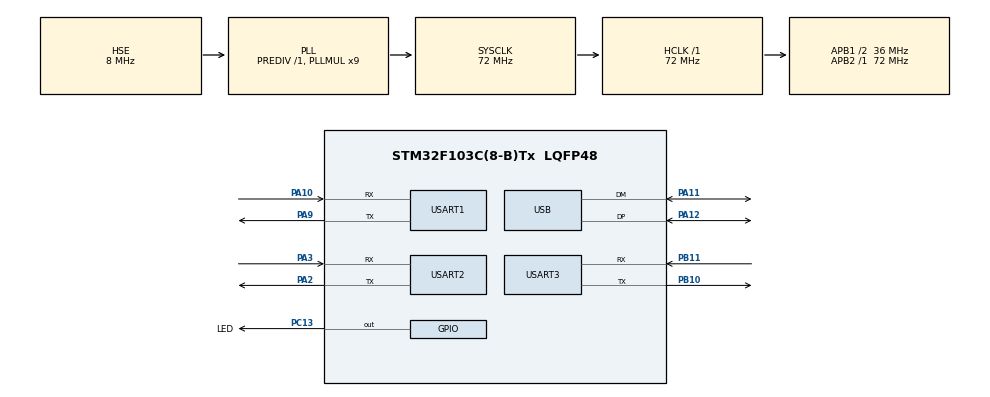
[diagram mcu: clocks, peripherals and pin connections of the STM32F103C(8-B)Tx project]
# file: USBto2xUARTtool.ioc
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Dma.Request0=USART1_TX
Dma.Request1=USART2_TX
Dma.Request2=USART3_TX
Dma.USART1_TX.0.Direction=DMA_MEMORY_TO_PERIPH
Dma.USART1_TX.0.Instance=DMA1_Channel4
Dma.USART1_TX.0.MemDataAlignment=DMA_MDATAALIGN_BYTE
Dma.USART1_TX.0.MemInc=DMA_MINC_ENABLE
Dma.USART1_TX.0.Mode=DMA_NORMAL
Dma.USART1_TX.0.PeriphDataAlignment=DMA_PDATAALIGN_BYTE
Dma.USART1_TX.0.PeriphInc=DMA_PINC_DISABLE
Dma.USART1_TX.0.Priority=DMA_PRIORITY_LOW
Dma.USART2_TX.1.Direction=DMA_MEMORY_TO_PERIPH
Dma.USART2_TX.1.Instance=DMA1_Channel7
Dma.USART2_TX.1.MemDataAlignment=DMA_MDATAALIGN_BYTE
Dma.USART2_TX.1.MemInc=DMA_MINC_ENABLE
Dma.USART2_TX.1.Mode=DMA_NORMAL
Dma.USART2_TX.1.PeriphDataAlignment=DMA_PDATAALIGN_BYTE
Dma.USART2_TX.1.PeriphInc=DMA_PINC_DISABLE
Dma.USART2_TX.1.Priority=DMA_PRIORITY_LOW
Dma.USART3_TX.2.Direction=DMA_MEMORY_TO_PERIPH
Dma.USART3_TX.2.Instance=DMA1_Channel2
Dma.USART3_TX.2.MemDataAlignment=DMA_MDATAALIGN_BYTE
Dma.USART3_TX.2.MemInc=DMA_MINC_ENABLE
Dma.USART3_TX.2.Mode=DMA_NORMAL
Dma.USART3_TX.2.PeriphDataAlignment=DMA_PDATAALIGN_BYTE
Dma.USART3_TX.2.PeriphInc=DMA_PINC_DISABLE
Dma.USART3_TX.2.Priority=DMA_PRIORITY_LOW
FREERTOS.Tasks01=defaultTask,24,128,StartDefaultTask,Default,NULL,Dynamic,NULL,NULL
Mcu.Family=STM32F1
Mcu.Name=STM32F103C(8-B)Tx
Mcu.Package=LQFP48
NVIC.DMA1_Channel2_IRQn=true\:5\:0\:false\:false\:true\:true\:false\:true\:true
NVIC.DMA1_Channel4_IRQn=true\:5\:0\:false\:false\:true\:true\:false\:true\:true
NVIC.DMA1_Channel7_IRQn=true\:5\:0\:false\:false\:true\:true\:false\:true\:true
NVIC.PriorityGroup=NVIC_PRIORITYGROUP_4
NVIC.USART1_IRQn=true\:5\:0\:false\:false\:true\:true\:true\:true\:true
NVIC.USART2_IRQn=true\:5\:0\:false\:false\:true\:true\:true\:true\:true
NVIC.USART3_IRQn=true\:5\:0\:false\:false\:true\:true\:true\:true\:true
NVIC.USB_LP_CAN1_RX0_IRQn=true\:5\:0\:false\:false\:true\:true\:false\:true\:true
PA10.Mode=Asynchronous
PA10.Signal=USART1_RX
PA11.Mode=Device
PA11.Signal=USB_DM
PA12.Mode=Device
PA12.Signal=USB_DP
PA13.Mode=Serial_Wire
PA13.Signal=SYS_JTMS-SWDIO
PA14.Mode=Serial_Wire
PA14.Signal=SYS_JTCK-SWCLK
PA2.Mode=Asynchronous
PA2.Signal=USART2_TX
PA3.Mode=Asynchronous
PA3.Signal=USART2_RX
PA9.Mode=Asynchronous
PA9.Signal=USART1_TX
PB10.Mode=Asynchronous
PB10.Signal=USART3_TX
PB11.Mode=Asynchronous
PB11.Signal=USART3_RX
PC13-TAMPER-RTC.GPIO_Label=LED
PC13-TAMPER-RTC.Signal=GPIO_Output
PD0-OSC_IN.Mode=HSE-External-Oscillator
PD0-OSC_IN.Signal=RCC_OSC_IN
PD1-OSC_OUT.Mode=HSE-External-Oscillator
PD1-OSC_OUT.Signal=RCC_OSC_OUT
ProjectManager.HeapSize=0x200
ProjectManager.StackSize=0x400
ProjectManager.TargetToolchain=Makefile
RCC.AHBFreq_Value=72000000
RCC.APB1CLKDivider=RCC_HCLK_DIV2
RCC.APB1Freq_Value=36000000
RCC.APB1TimFreq_Value=72000000
RCC.APB2Freq_Value=72000000
RCC.APB2TimFreq_Value=72000000
RCC.HCLKFreq_Value=72000000
RCC.PLLMUL=RCC_PLL_MUL9
RCC.SYSCLKFreq_VALUE=72000000
RCC.SYSCLKSource=RCC_SYSCLKSOURCE_PLLCLK
RCC.USBFreq_Value=48000000
RCC.USBPrescaler=RCC_USBCLKSOURCE_PLL_DIV1_5
USART1.VirtualMode=VM_ASYNC
USART2.VirtualMode=VM_ASYNC
USART3.VirtualMode=VM_ASYNC
USB_DEVICE.CLASS_NAME_FS=CDC
USB_DEVICE.VirtualMode=Cdc
USB_DEVICE.VirtualModeFS=Cdc_FS
VP_CRC_VS_CRC.Mode=CRC_Activate
VP_FREERTOS_VS_CMSIS_V2.Mode=CMSIS_V2
VP_USB_DEVICE_VS_USB_DEVICE_CDC_FS.Mode=CDC_FS
board=custom

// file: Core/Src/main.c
/* USER CODE BEGIN Header */
/**
  ******************************************************************************
  * @file           : main.c
  * @brief          : Main program body
  ******************************************************************************
  * @attention
  *
  * Copyright (c) 2026 STMicroelectronics.
  * All rights reserved.
  *
  * This software is licensed under terms that can be found in the LICENSE file
  * in the root directory of this software component.
  * If no LICENSE file comes with this software, it is provided AS-IS.
  *
  ******************************************************************************
  */
/* USER CODE END Header */
#include "main.h"
#include "cmsis_os.h"
#include "app.h"
#include "crc.h"
#include "dma.h"
#include "usart.h"
#include "usb_device.h"
#include "gpio.h"

void SystemClock_Config(void);
void MX_FREERTOS_Init(void);

int main(void)
{
  /* USER CODE BEGIN 1 */

  /* First statement of the application: register level only, so this line also
     appears when everything after it fails.  If the console shows the
     bootloader's "starting application" line and nothing else, the jump itself
     is the problem; if these lines appear, the jump worked. */
  App_EarlyTrace("[app] reset vector reached main\r\n");

  /* USER CODE END 1 */

  /* MCU Configuration--------------------------------------------------------*/

  /* Reset of all peripherals, Initializes the Flash interface and the Systick. */
  HAL_Init();

  /* USER CODE BEGIN Init */

  App_EarlyTrace("[app] HAL_Init ok\r\n");

  /* USER CODE END Init */

  /* Configure the system clock */
  SystemClock_Config();

  /* USER CODE BEGIN SysInit */

  App_EarlyTrace("[app] clock setup ok\r\n");

  /* USER CODE END SysInit */

  /* Initialize all configured peripherals */
  MX_GPIO_Init();
  MX_DMA_Init();
  MX_CRC_Init();
  MX_USART1_UART_Init();
  MX_USART2_UART_Init();
  MX_USART3_UART_Init();
  /* USER CODE BEGIN 2 */

  App_EarlyTrace("[app] GPIO/DMA/CRC/UARTs ok\r\n");

  /* First sign of life after the bootloader jump: if this line never appears on
     UART1, the application did not reach main() (or the clock setup failed).
     The date/time always reflects this build, so it identifies the running
     application image.  Printed before any other activity so a reset during the
     LED burst cannot hide it. */
  App_BootLog("[app] build " __DATE__ " " __TIME__ ", clock and UARTs ready\r\n");

  /* Hardware-only sign of life: three fast blinks mean the bootloader jump
     reached main() (the bootloader itself leaves the LED permanently on). */
  App_BlinkBurst(3U);
  /* USER CODE END 2 */

  /* Init scheduler */
  osKernelInitialize();  /* Call init function for freertos objects (in freertos.c) */
  MX_FREERTOS_Init();

  /* Start scheduler */
  osKernelStart();

  /* We should never get here as control is now taken by the scheduler */
  /* Infinite loop */
  while (1)
  {

  }
}

void SystemClock_Config(void)
{
  RCC_OscInitTypeDef RCC_OscInitStruct = {0};
  RCC_ClkInitTypeDef RCC_ClkInitStruct = {0};
  RCC_PeriphCLKInitTypeDef PeriphClkInit = {0};

  /** Initializes the RCC Oscillators according to the specified parameters
  * in the RCC_OscInitTypeDef structure.
  */
  RCC_OscInitStruct.OscillatorType = RCC_OSCILLATORTYPE_HSE;
  RCC_OscInitStruct.HSEState = RCC_HSE_ON;
  RCC_OscInitStruct.HSEPredivValue = RCC_HSE_PREDIV_DIV1;
  RCC_OscInitStruct.HSIState = RCC_HSI_ON;
  RCC_OscInitStruct.PLL.PLLState = RCC_PLL_ON;
  RCC_OscInitStruct.PLL.PLLSource = RCC_PLLSOURCE_HSE;
  RCC_OscInitStruct.PLL.PLLMUL = RCC_PLL_MUL9;
  if (HAL_RCC_OscConfig(&RCC_OscInitStruct) != HAL_OK)
  {
    Error_Handler();
  }

  /** Initializes the CPU, AHB and APB buses clocks
  */
  RCC_ClkInitStruct.ClockType = RCC_CLOCKTYPE_HCLK|RCC_CLOCKTYPE_SYSCLK
                              |RCC_CLOCKTYPE_PCLK1|RCC_CLOCKTYPE_PCLK2;
  RCC_ClkInitStruct.SYSCLKSource = RCC_SYSCLKSOURCE_PLLCLK;
  RCC_ClkInitStruct.AHBCLKDivider = RCC_SYSCLK_DIV1;
  RCC_ClkInitStruct.APB1CLKDivider = RCC_HCLK_DIV2;
  RCC_ClkInitStruct.APB2CLKDivider = RCC_HCLK_DIV1;

  if (HAL_RCC_ClockConfig(&RCC_ClkInitStruct, FLASH_LATENCY_2) != HAL_OK)
  {
    Error_Handler();
  }
  PeriphClkInit.PeriphClockSelection = RCC_PERIPHCLK_USB;
  PeriphClkInit.UsbClockSelection = RCC_USBCLKSOURCE_PLL_DIV1_5;
  if (HAL_RCCEx_PeriphCLKConfig(&PeriphClkInit) != HAL_OK)
  {
    Error_Handler();
  }
}

void Error_Handler(void)
{
  /* USER CODE BEGIN Error_Handler_Debug */
  /* User can add his own implementation to report the HAL error return state */
  App_BootLog("[app] Error_Handler: HAL init failed, LED stays on\r\n");

  /* LED on (active low) as a signal that does not need a terminal. */
  HAL_GPIO_WritePin(LED_GPIO_Port, LED_Pin, GPIO_PIN_RESET);

  __disable_irq();
  while (1)
  {
  }
  /* USER CODE END Error_Handler_Debug */
}

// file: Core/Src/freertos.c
/* USER CODE BEGIN Header */
/**
  ******************************************************************************
  * File Name          : freertos.c
  * Description        : Code for freertos applications
  ******************************************************************************
  * @attention
  *
  * Copyright (c) 2026 STMicroelectronics.
  * All rights reserved.
  *
  * This software is licensed under terms that can be found in the LICENSE file
  * in the root directory of this software component.
  * If no LICENSE file comes with this software, it is provided AS-IS.
  *
  ******************************************************************************
  */
/* USER CODE END Header */

#include "FreeRTOS.h"
#include "task.h"
#include "main.h"
#include "cmsis_os.h"

/* USER CODE BEGIN Includes */
#include "app.h"
/* USER CODE END Includes */

/* Definitions for defaultTask */
osThreadId_t defaultTaskHandle;
const osThreadAttr_t defaultTask_attributes = {
  .name = "defaultTask",
  .stack_size = 128 * 4,
  .priority = (osPriority_t) osPriorityNormal,
};

void StartDefaultTask(void *argument);

extern void MX_USB_DEVICE_Init(void);
void MX_FREERTOS_Init(void); /* (MISRA C 2004 rule 8.1) */

void MX_FREERTOS_Init(void) {

  /* Create the thread(s) */
  /* creation of defaultTask */
  defaultTaskHandle = osThreadNew(StartDefaultTask, NULL, &defaultTask_attributes);

}

void StartDefaultTask(void *argument)
{
  /* init code for USB_DEVICE */
  /* USER CODE BEGIN StartDefaultTask */
  /* Starts the shell, the USB <-> UART bridge, the LED timer and USB. */
  App_Init();
  /* Infinite loop */
  for(;;)
  {
    osDelay(1);
  }
  /* USER CODE END StartDefaultTask */
}
